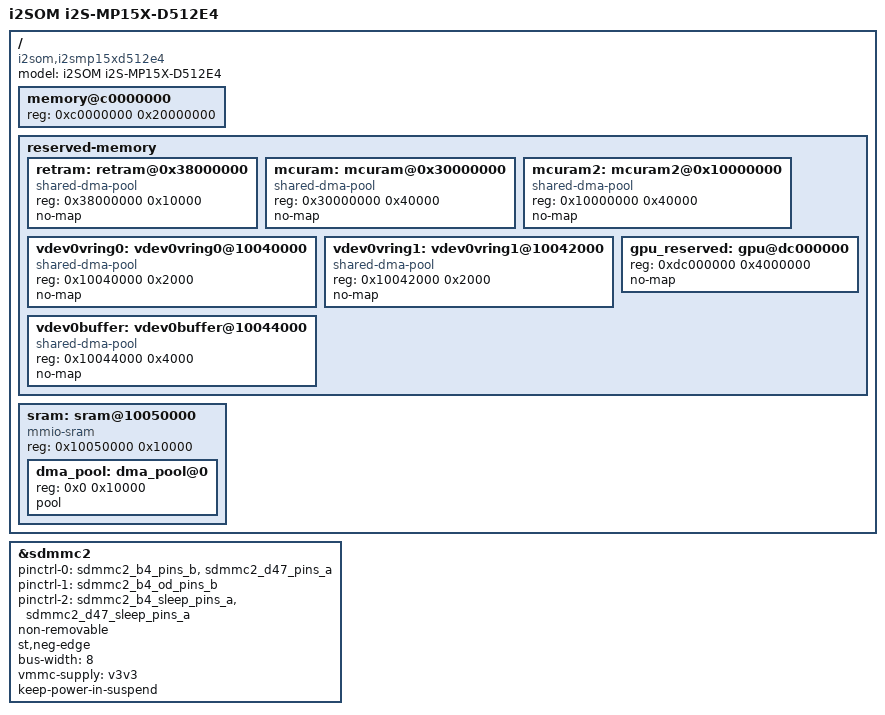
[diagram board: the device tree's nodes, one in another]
// SPDX-License-Identifier: (GPL-2.0+ OR BSD-3-Clause)
/*
 * Copyright (C) i2SOM 2018 - All Rights Reserved
 * Author: Steve Chen <steve.chen@i2som.tech>.
 */

/dts-v1/;

#include "stm32mp157c.dtsi"
#include "stm32mp157c-m4-srm.dtsi"
#include "stm32mp157caa-pinctrl.dtsi"

/ {
	model = "i2SOM i2S-MP15X-D512E4";
	compatible = "i2som,i2smp15xd512e4", "st,stm32mp157";

	memory@c0000000 {
		reg = <0xc0000000 0x20000000>;
	};

	reserved-memory {
		#address-cells = <1>;
		#size-cells = <1>;
		ranges;

		retram: retram@0x38000000 {
			compatible = "shared-dma-pool";
			reg = <0x38000000 0x10000>;
			no-map;
		};

		mcuram: mcuram@0x30000000 {
			compatible = "shared-dma-pool";
			reg = <0x30000000 0x40000>;
			no-map;
		};

		mcuram2: mcuram2@0x10000000 {
			compatible = "shared-dma-pool";
			reg = <0x10000000 0x40000>;
			no-map;
		};

		vdev0vring0: vdev0vring0@10040000 {
			compatible = "shared-dma-pool";
			reg = <0x10040000 0x2000>;
			no-map;
		};

		vdev0vring1: vdev0vring1@10042000 {
			compatible = "shared-dma-pool";
			reg = <0x10042000 0x2000>;
			no-map;
		};

		vdev0buffer: vdev0buffer@10044000 {
			compatible = "shared-dma-pool";
			reg = <0x10044000 0x4000>;
			no-map;
		};

		gpu_reserved: gpu@dc000000 {
			reg = <0xdc000000 0x4000000>;
			no-map;
		};
	};

	sram: sram@10050000 {
		compatible = "mmio-sram";
		reg = <0x10050000 0x10000>;
		#address-cells = <1>;
		#size-cells = <1>;
		ranges = <0 0x10050000 0x10000>;

		dma_pool: dma_pool@0 {
			reg = <0x0 0x10000>;
			pool;
		};
	};

};

/* emmc */
&sdmmc2 {
	pinctrl-names = "default", "opendrain", "sleep";
	pinctrl-0 = <&sdmmc2_b4_pins_b &sdmmc2_d47_pins_a>;
	pinctrl-1 = <&sdmmc2_b4_od_pins_b>;
	pinctrl-2 = <&sdmmc2_b4_sleep_pins_a &sdmmc2_d47_sleep_pins_a>;
	non-removable;
	st,neg-edge;
	bus-width = <8>;
	vmmc-supply = <&v3v3>;
	keep-power-in-suspend;
	status = "okay";
};

